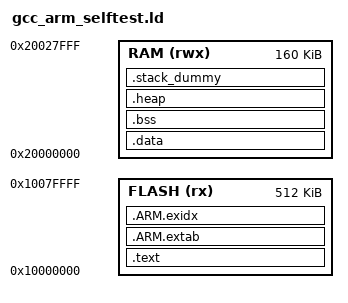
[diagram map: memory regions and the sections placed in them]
/* Linker script for M487 USB Composite Device with Self-Test Result Section
 *
 * Based on: gcc_arm.ld from Nuvoton M480 BSP
 * Modified: RAM size increased to 160 KB (0x28000), .selftest section added
 *
 * Key modification:
 *   - RAM: ORIGIN=0x20000000, LENGTH=0x28000 (160 KB)
 *   - .selftest section placed at 0x2000FFF0 (last 16 bytes of SRAM)
 *     This allows MSC Debug Channel to read self-test results
 *     via DBG_READ_MEM command without any special firmware support.
 *
 * Usage:
 *   arm-none-eabi-ld -Tgcc_arm_selftest.ld ... or
 *   GCC_ARM_LD = -Tgcc_arm_selftest.ld (in Makefile)
 */

MEMORY
{
  FLASH (rx) : ORIGIN = 0x10000000, LENGTH = 0x80000   /* 512 KB @ 0x10000000 */
  RAM (rwx)  : ORIGIN = 0x20000000, LENGTH = 0x28000   /* 160 KB @ 0x20000000 */
}

/* Library configurations */
GROUP(libgcc.a libc.a libm.a libnosys.a)

ENTRY(Reset_Handler)

SECTIONS
{
	.text :
	{
		KEEP(*(.vectors))
		__Vectors_End = .;
		__Vectors_Size = __Vectors_End - __Vectors;
		__end__ = .;

		*(.text*)

		KEEP(*(.init))
		KEEP(*(.fini))

		/* .ctors */
		*crtbegin.o(.ctors)
		*crtbegin?.o(.ctors)
		*(EXCLUDE_FILE(*crtend?.o *crtend.o) .ctors)
		*(SORT(.ctors.*))
		*(.ctors)

		/* .dtors */
 		*crtbegin.o(.dtors)
 		*crtbegin?.o(.dtors)
 		*(EXCLUDE_FILE(*crtend?.o *crtend.o) .dtors)
		*(SORT(.dtors.*))
		*(.dtors)

		*(.rodata*)

		KEEP(*(.eh_frame*))
	} > FLASH

	.ARM.extab :
	{
		*(.ARM.extab* .gnu.linkonce.armextab.*)
	} > FLASH

	__exidx_start = .;
	.ARM.exidx :
	{
		*(.ARM.exidx* .gnu.linkonce.armexidx.*)
	} > FLASH
	__exidx_end = .;

	__etext = .;

	.data : AT (__etext)
	{
		__data_start__ = .;
		*(vtable)
		*(.data*)

		. = ALIGN(4);
		/* preinit data */
		PROVIDE_HIDDEN (__preinit_array_start = .);
		KEEP(*(.preinit_array))
		PROVIDE_HIDDEN (__preinit_array_end = .);

		. = ALIGN(4);
		/* init data */
		PROVIDE_HIDDEN (__init_array_start = .);
		KEEP(*(SORT(.init_array.*)))
		KEEP(*(.init_array))
		PROVIDE_HIDDEN (__init_array_end = .);

		. = ALIGN(4);
		/* finit data */
		PROVIDE_HIDDEN (__fini_array_start = .);
		KEEP(*(SORT(.fini_array.*)))
		KEEP(*(.fini_array))
		PROVIDE_HIDDEN (__fini_array_end = .);

		KEEP(*(.jcr*))
		. = ALIGN(4);
		/* All data end */
		__data_end__ = .;

	} > RAM

	.bss :
	{
		. = ALIGN(4);
		__bss_start__ = .;
		*(.bss*)
		*(COMMON)
		. = ALIGN(4);
		__bss_end__ = .;
	} > RAM

	/* -------------------------------------------------------------------------- */
	/* Self-Test Result Section (NOldkby linker)                                   */
	/* Note: Self-test results are written directly to 0x2000FFF0 at runtime.      */
	/* This section is kept for reference but not used (NOLOAD).                   */
	/* -------------------------------------------------------------------------- */

	.heap (COPY):
	{
		__HeapBase = .;
		__end__ = .;
		end = __end__;
		KEEP(*(.heap*))
		__HeapLimit = .;
	} > RAM

	/* .stack_dummy section doesn't contains any symbols. It is only
	 * used for linker to calculate size of stack sections, and assign
	 * values to stack symbols later */
	.stack_dummy (COPY):
	{
		KEEP(*(.stack*))
	} > RAM

	/* Set stack top to end of RAM, and stack limit move down by
	 * size of stack_dummy section */
	__StackTop = ORIGIN(RAM) + LENGTH(RAM);
	__StackLimit = __StackTop - SIZEOF(.stack_dummy);
	PROVIDE(__stack = __StackTop);

	/* Check if data + heap + stack exceeds RAM limit */
	ASSERT(__StackLimit >= __HeapLimit, "region RAM overflowed with stack")
}
